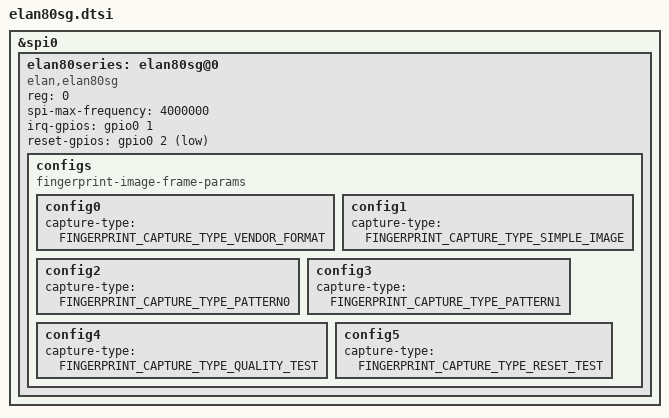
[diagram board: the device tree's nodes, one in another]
/* Copyright 2025 The ChromiumOS Authors
 * Use of this source code is governed by a BSD-style license that can be
 * found in the LICENSE file.
 */

#define ELAN80SG_COMMON_IMAGE_PROPS \
	width = <80>; \
	height = <80>; \
	bits-per-pixel = <14>; \
	frame-size = <12800>; \
	image-data-offset-bytes = <0>; \
	v4l2-pixel-format = "V4L2_PIX_FMT_GREY";

&spi0 {
	elan80series: elan80sg@0 {
		compatible = "elan,elan80sg";
		reg = <0>;
		spi-max-frequency = <4000000>;

		configs {
			compatible = "fingerprint-image-frame-params";
			config0 {
				ELAN80SG_COMMON_IMAGE_PROPS
				capture-type = "FINGERPRINT_CAPTURE_TYPE_VENDOR_FORMAT";
			};
			config1 {
				ELAN80SG_COMMON_IMAGE_PROPS
				capture-type = "FINGERPRINT_CAPTURE_TYPE_SIMPLE_IMAGE";
			};
			config2 {
				ELAN80SG_COMMON_IMAGE_PROPS
				capture-type = "FINGERPRINT_CAPTURE_TYPE_PATTERN0";
			};
			config3 {
				ELAN80SG_COMMON_IMAGE_PROPS
				capture-type = "FINGERPRINT_CAPTURE_TYPE_PATTERN1";
			};
			config4 {
				ELAN80SG_COMMON_IMAGE_PROPS
				capture-type = "FINGERPRINT_CAPTURE_TYPE_QUALITY_TEST";
			};
			config5 {
				ELAN80SG_COMMON_IMAGE_PROPS
				capture-type = "FINGERPRINT_CAPTURE_TYPE_RESET_TEST";
			};
		};

		irq-gpios = <&gpio0 1 GPIO_ACTIVE_HIGH>;
		reset-gpios = <&gpio0 2 GPIO_ACTIVE_LOW>;
	};
};
